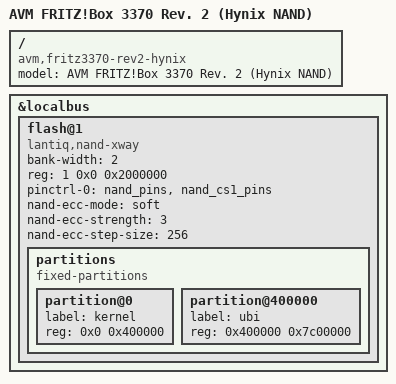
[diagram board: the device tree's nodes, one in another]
/dts-v1/;

#include "vr9_avm_fritz3370-rev2.dtsi"

/ {
	compatible = "avm,fritz3370-rev2-hynix", "avm,fritz3370-rev2", "lantiq,xway", "lantiq,vr9";
	model = "AVM FRITZ!Box 3370 Rev. 2 (Hynix NAND)";
};

&localbus {
	flash@1 {
		compatible = "lantiq,nand-xway";
		bank-width = <2>;
		reg = <1 0x0 0x2000000>;

		pinctrl-0 = <&nand_pins>, <&nand_cs1_pins>;
		pinctrl-names = "default";

		nand-ecc-mode = "soft";
		nand-ecc-strength = <3>;
		nand-ecc-step-size = <256>;

		partitions {
			compatible = "fixed-partitions";
			#address-cells = <1>;
			#size-cells = <1>;

			partition@0 {
				label = "kernel";
				reg = <0x0 0x400000>;
			};

			partition@400000 {
				label = "ubi";
				reg = <0x400000 0x7c00000>;
			};
		};
	};
};
